# PRU_ICSSG0_PR1_CFG_SLV_local register map
Vendor: Texas Instruments
Peripheral module from a debugger description file (folder am65x).
Registers are 32-bit, read-write, reset 0x0 unless marked. A register's access mark holds for its fields unless they carry their own. Offsets are as the file gives them; lines under a group give offsets from that group; [hi:lo] are bit positions; {n}, {i} and the like mark numbered series; 'fields as' and 'values as' point back to an identical list; <NAME> marks a mode.

## PRU_ICSSG0_PR1_CFG_SLV
0x00 ICSSG_PID_REG ro reset 0x6B00C900 — PID Register.
  [31:0] ICSS_IDVER — Module ID field
0x04 ICSSG_HWDIS_REG ro reset not defined — HW Disable Register
  [7:0] HWDIS — Read the state of the efuse bits which drive pr1_hw_disable[7:0]
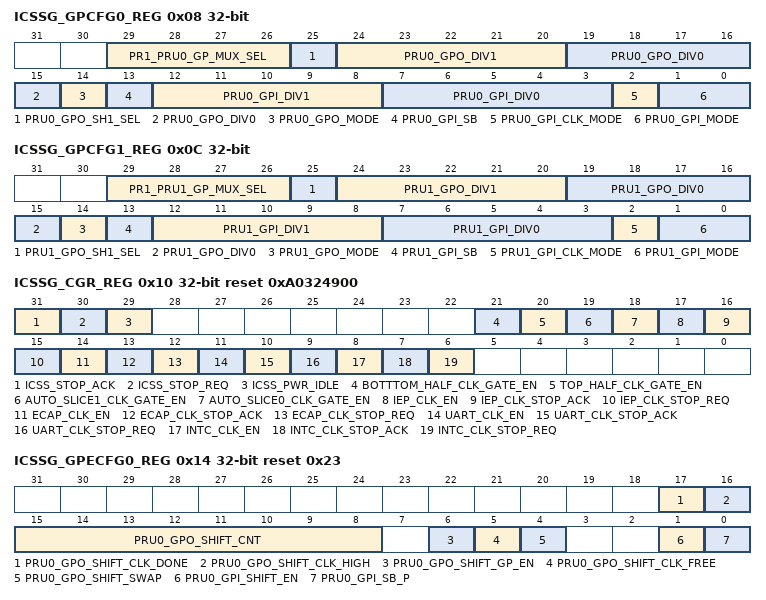
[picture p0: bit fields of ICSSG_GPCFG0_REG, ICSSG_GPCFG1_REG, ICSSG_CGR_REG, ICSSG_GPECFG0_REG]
0x08 ICSSG_GPCFG0_REG access not given — GP Configuration 0 Register
  [29:26] PR1_PRU0_GP_MUX_SEL rw — Controls the icss_wrap mux sel
  [25] PRU0_GPO_SH1_SEL ro — This defines which shadow register is currently getting used for GPO shifting.
  [24:20] PRU0_GPO_DIV1 rw — Divisor value , divide by PRU0_GPO_DIV1 + 1
  [19:15] PRU0_GPO_DIV0 rw — Divisor value , divide by PRU0_GPO_DIV0 + 1
  [14] PRU0_GPO_MODE rw — 0hh = Parallel output mode
  [13] PRU0_GPI_SB — PRU0_GPI_SB set when first capture on 1 on r31_status[0] (access RW1C)
  [12:8] PRU0_GPI_DIV1 rw — Divisor value , divide by PRU0_GPI_DIV1 + 1
  [7:3] PRU0_GPI_DIV0 rw — Divisor value , divide by PRU0_GPI_DIV0 + 1
  [2] PRU0_GPI_CLK_MODE rw — Parallel 16-bit capture mode clock edge
  [1:0] PRU0_GPI_MODE rw — 0hh = Direct connect of pru&lt;n&gt;_r31_status[29:0]
0x0C ICSSG_GPCFG1_REG access not given — GP Configuration 1 Register
  [29:26] PR1_PRU1_GP_MUX_SEL rw — Controls the icss_wrap mux sel
  [25] PRU1_GPO_SH1_SEL ro — This defines which shadow register is currently getting used for GPO shifting.
  [24:20] PRU1_GPO_DIV1 rw — Divisor value , divide by PRU1_GPO_DIV1 + 1
  [19:15] PRU1_GPO_DIV0 rw — Divisor value , divide by PRU1_GPO_DIV0 + 1
  [14] PRU1_GPO_MODE rw — 0hh = Parallel output mode
  [13] PRU1_GPI_SB — PRU1_GPI_SB set when first capture on 1 on r31_status[0] (access RW1C)
  [12:8] PRU1_GPI_DIV1 rw — Divisor value , divide by PRU1_GPI_DIV1 + 1
  [7:3] PRU1_GPI_DIV0 rw — Divisor value , divide by PRU1_GPI_DIV0 + 1
  [2] PRU1_GPI_CLK_MODE rw — Parallel 16-bit capture mode clock edge
  [1:0] PRU1_GPI_MODE rw — 0hh = Direct connect of pru&lt;n&gt;_r31_status[29:0]
0x10 ICSSG_CGR_REG access per field reset 0xA0324900 — Clock Gating Register
  [31] ICSS_STOP_ACK rw — ICSS
  [30] ICSS_STOP_REQ ro — ICSS
  [29] ICSS_PWR_IDLE rw — ICSS
  [21] BOTTTOM_HALF_CLK_GATE_EN rw — Bottom Clock Gate for slice 0 and 1 0 = Disable Clock 1 = Enable Clock
  [20] TOP_HALF_CLK_GATE_EN rw — Top Clock Gate for slice 0 and 1 0 = Disable Clock 1 = Enable Clock
  [19] AUTO_SLICE1_CLK_GATE_EN rw — Auto Clock Gate for slice 1 Ethernet 0 = Disable Clock 1 = Enable Auto Clock
  [18] AUTO_SLICE0_CLK_GATE_EN rw — Auto Clock Gate for slice 0 Ethernet 0 = Disable Clock 1 = Enable Clock
  [17] IEP_CLK_EN rw — IEP
  [16] IEP_CLK_STOP_ACK ro — IEP
  [15] IEP_CLK_STOP_REQ rw — IEP
  [14] ECAP_CLK_EN rw — ECAP
  [13] ECAP_CLK_STOP_ACK ro — ECAP
  [12] ECAP_CLK_STOP_REQ rw — ECAP
  [11] UART_CLK_EN rw — UART
  [10] UART_CLK_STOP_ACK ro — UART
  [9] UART_CLK_STOP_REQ rw — UART
  [8] INTC_CLK_EN rw — INTC
  [7] INTC_CLK_STOP_ACK ro — INTC
  [6] INTC_CLK_STOP_REQ rw — INTC
0x14 ICSSG_GPECFG0_REG reset 0x23 — GP Enc Configuration 0 Register
  [17] PRU0_GPO_SHIFT_CLK_DONE — Shift Clock Done is active when PRU0_GPO_SHIFT_CNT is none zero
  [16] PRU0_GPO_SHIFT_CLK_HIGH — Shift Clock Stop High
  [15:8] PRU0_GPO_SHIFT_CNT — Shift Bit Count
  [6] PRU0_GPO_SHIFT_GP_EN — Enable pru&lt;n&gt;r30[15:2] control during shift out mode
  [5] PRU0_GPO_SHIFT_CLK_FREE — Free Running Clock Mode
  [4] PRU0_GPO_SHIFT_SWAP — 0hh = No Swap
  [1] PRU0_GPI_SHIFT_EN — GPI Shift In Enable
  [0] PRU0_GPI_SB_P — GPI Shift In Start Bit Polarity
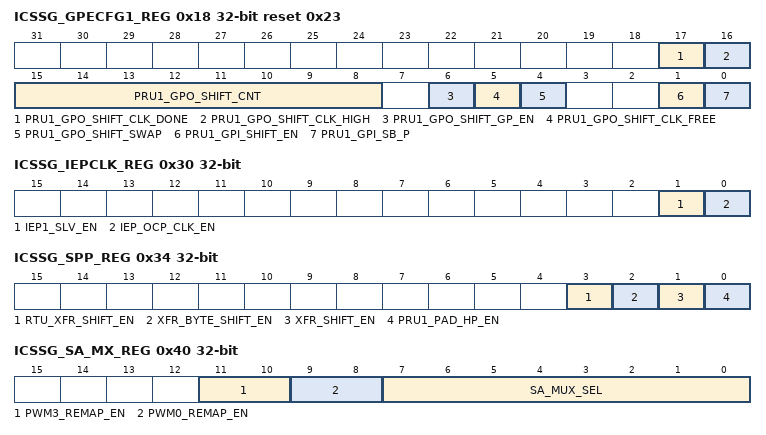
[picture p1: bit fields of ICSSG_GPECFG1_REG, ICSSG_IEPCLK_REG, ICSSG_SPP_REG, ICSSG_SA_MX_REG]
0x18 ICSSG_GPECFG1_REG reset 0x23 — GP Enc Configuration 1 Register
  [17] PRU1_GPO_SHIFT_CLK_DONE — Shift Clock Done is active when PRU1_GPO_SHIFT_CNT is none zero
  [16] PRU1_GPO_SHIFT_CLK_HIGH — Shift Clock Stop High
  [15:8] PRU1_GPO_SHIFT_CNT — Shift Bit Count
  [6] PRU1_GPO_SHIFT_GP_EN — Enable pru&lt;n&gt;r30[15:2] control during shift out mode
  [5] PRU1_GPO_SHIFT_CLK_FREE — Free Running Clock Mode
  [4] PRU1_GPO_SHIFT_SWAP — 0hh = No Swap
  [1] PRU1_GPI_SHIFT_EN — GPI Shift In Enable
  [0] PRU1_GPI_SB_P — GPI Shift In Start Bit Polarity
0x2C ICSSG_MII_RT_REG reset 0x1 — MII_RT Event Enable Register
  [0] MII_RT_EVENT_EN — Enables the MII_RT Events to the INTC
0x30 ICSSG_IEPCLK_REG — IEP Configuration Register
  [1] IEP1_SLV_EN — IEP1 Master Counter Slave enable
  [0] IEP_OCP_CLK_EN — Defines the source of the IEP CLK
0x34 ICSSG_SPP_REG — Scratchpad Priority and Shift Register
  [3] RTU_XFR_SHIFT_EN — Shift enable using R0[4:0] to define the number of 32-bit offset for XIN and XOUT operations.
  [2] XFR_BYTE_SHIFT_EN — Shift enable using R0[6:0] to define the number of 8-bit offset for XIN and XOUT operations.
  [1] XFR_SHIFT_EN — Shift enable using R0[4:0] to define the number of 32-bit offset for XIN and XOUT operations.
  [0] PRU1_PAD_HP_EN — Reserved
0x3C ICSSG_CORE_SYNC_REG — CoreSync Configuration Register.
  [0] CORE_VBUSP_SYNC_EN — Defines the source of the internal CORE CLK
0x40 ICSSG_SA_MX_REG — SA Mux Selection Register.
  [11:10] PWM3_REMAP_EN — PWM3_REMAP_EN controls PRU_ICSSG internal wrapper multiplexing logic.
  [9:8] PWM0_REMAP_EN — PWM0_REMAP_EN controls PRU_ICSSG internal wrapper multiplexing logic.
  [7:0] SA_MUX_SEL — Reserved
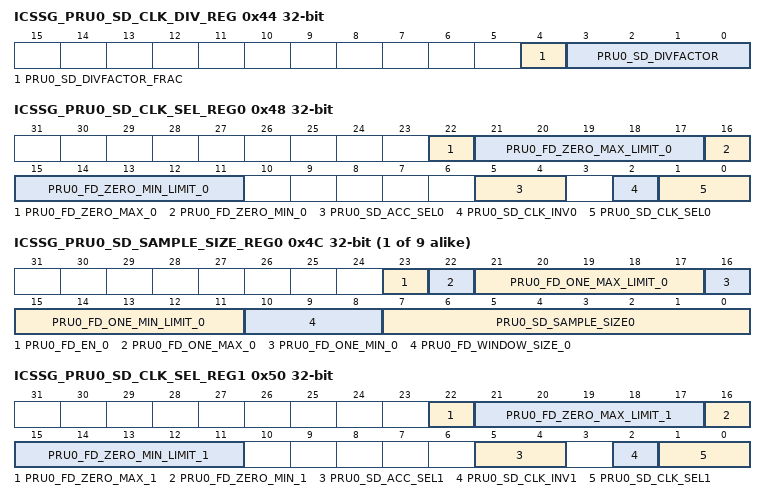
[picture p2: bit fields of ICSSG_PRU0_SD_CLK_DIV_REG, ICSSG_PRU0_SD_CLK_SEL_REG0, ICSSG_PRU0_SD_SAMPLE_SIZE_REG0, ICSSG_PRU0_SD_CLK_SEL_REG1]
0x44 ICSSG_PRU0_SD_CLK_DIV_REG — SD Register.
  [4] PRU0_SD_DIVFACTOR_FRAC, [3:0] PRU0_SD_DIVFACTOR
0x48 ICSSG_PRU0_SD_CLK_SEL_REG0 — PRU0 FD, ACC and Clock Selection Register 0.
  [22] PRU0_FD_ZERO_MAX_0 — Fast Detect Zero Count Max Threshold Hit
  [21:17] PRU0_FD_ZERO_MAX_LIMIT_0 — Fast Detect Zero Count Max Threshold
  [16] PRU0_FD_ZERO_MIN_0 — Fast Detect Zero Count Min Threshold Hit
  [15:11] PRU0_FD_ZERO_MIN_LIMIT_0 — Fast Detect Zero Count Min Threshold
  [5:4] PRU0_SD_ACC_SEL0 — 0h = acc3 is selected
  [2] PRU0_SD_CLK_INV0 — Optional clock inversion post clock selection multiplexer
  [1:0] PRU0_SD_CLK_SEL0 — Selects the clock source
{0x4C+8i} ICSSG_PRU0_SD_SAMPLE_SIZE_REG{i} (i=0..8) — PRU0 FD and Over Sample Size Register {i}.
  [23] PRU0_FD_EN_{i} — Fast Detect One Enable
  [22] PRU0_FD_ONE_MAX_{i} — Fast Detect One Count Max Threshold Hit
  [21:17] PRU0_FD_ONE_MAX_LIMIT_{i} — Fast Detect One Count Max Threshold
  [16] PRU0_FD_ONE_MIN_{i} — Fast Detect One Count Min Threshold Hit
  [15:11] PRU0_FD_ONE_MIN_LIMIT_{i} — Fast Detect One Count Min Threshold
  [10:8] PRU0_FD_WINDOW_SIZE_{i} — Fast Detect Window Size
  [7:0] PRU0_SD_SAMPLE_SIZE{i} — Over Sample Rate
0x50 ICSSG_PRU0_SD_CLK_SEL_REG1 — PRU0 FD, ACC and Clock Selection Register 1.
  [22] PRU0_FD_ZERO_MAX_1 — Fast Detect Zero Count Max Threshold Hit
  [21:17] PRU0_FD_ZERO_MAX_LIMIT_1 — Fast Detect Zero Count Max Threshold
  [16] PRU0_FD_ZERO_MIN_1 — Fast Detect Zero Count Min Threshold Hit
  [15:11] PRU0_FD_ZERO_MIN_LIMIT_1 — Fast Detect Zero Count Min Threshold
  [5:4] PRU0_SD_ACC_SEL1 — 0h = acc3 is selected
  [2] PRU0_SD_CLK_INV1 — Optional clock inversion post clock selection multiplexer
  [1:0] PRU0_SD_CLK_SEL1 — Selects the clock source
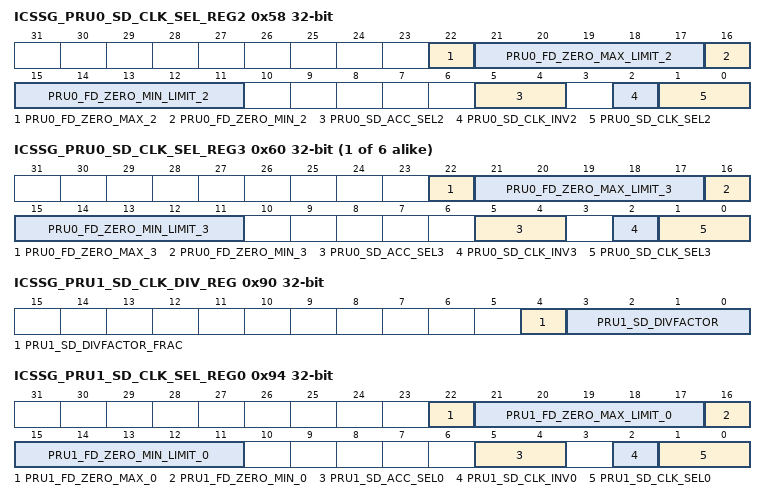
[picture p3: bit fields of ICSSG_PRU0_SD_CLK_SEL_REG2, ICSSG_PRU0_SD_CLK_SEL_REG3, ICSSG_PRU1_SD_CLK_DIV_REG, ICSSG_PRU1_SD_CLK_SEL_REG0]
0x58 ICSSG_PRU0_SD_CLK_SEL_REG2 — PRU0 FD, ACC and Clock Selection Register 2
  [22] PRU0_FD_ZERO_MAX_2 — Fast Detect Zero Count Max Threshold Hit
  [21:17] PRU0_FD_ZERO_MAX_LIMIT_2 — Fast Detect Zero Count Max Threshold
  [16] PRU0_FD_ZERO_MIN_2 — Fast Detect Zero Count Min Threshold Hit
  [15:11] PRU0_FD_ZERO_MIN_LIMIT_2 — Fast Detect Zero Count Min Threshold
  [5:4] PRU0_SD_ACC_SEL2 — 0h = acc3 is selected
  [2] PRU0_SD_CLK_INV2 — Optional clock inversion post clock selection multiplexer
  [1:0] PRU0_SD_CLK_SEL2 — Selects the clock source
{0x48+8i} ICSSG_PRU0_SD_CLK_SEL_REG{i} (i=3..8) — PRU0 FD, ACC and Clock Selection Register {i}.
  [22] PRU0_FD_ZERO_MAX_{i} — Fast Detect Zero Count Max Threshold Hit
  [21:17] PRU0_FD_ZERO_MAX_LIMIT_{i} — Fast Detect Zero Count Max Threshold
  [16] PRU0_FD_ZERO_MIN_{i} — Fast Detect Zero Count Min Threshold Hit
  [15:11] PRU0_FD_ZERO_MIN_LIMIT_{i} — Fast Detect Zero Count Min Threshold
  [5:4] PRU0_SD_ACC_SEL{i} — 0h = acc3 is selected
  [2] PRU0_SD_CLK_INV{i} — Optional clock inversion post clock selection multiplexer
  [1:0] PRU0_SD_CLK_SEL{i} — Selects the clock source
0x90 ICSSG_PRU1_SD_CLK_DIV_REG — SD Register.
  [4] PRU1_SD_DIVFACTOR_FRAC, [3:0] PRU1_SD_DIVFACTOR
0x94 ICSSG_PRU1_SD_CLK_SEL_REG0 — PRU1 FD, ACC and Clock Selection Register 0
  [22] PRU1_FD_ZERO_MAX_0 — Fast Detect Zero Count Max Threshold Hit
  [21:17] PRU1_FD_ZERO_MAX_LIMIT_0 — Fast Detect Zero Count Max Threshold
  [16] PRU1_FD_ZERO_MIN_0 — Fast Detect Zero Count Min Threshold Hit
  [15:11] PRU1_FD_ZERO_MIN_LIMIT_0 — Fast Detect Zero Count Min Threshold
  [5:4] PRU1_SD_ACC_SEL0 — 0h = acc3 is selected
  [2] PRU1_SD_CLK_INV0 — Optional clock inversion post clock selection multiplexer
  [1:0] PRU1_SD_CLK_SEL0 — Selects the clock source
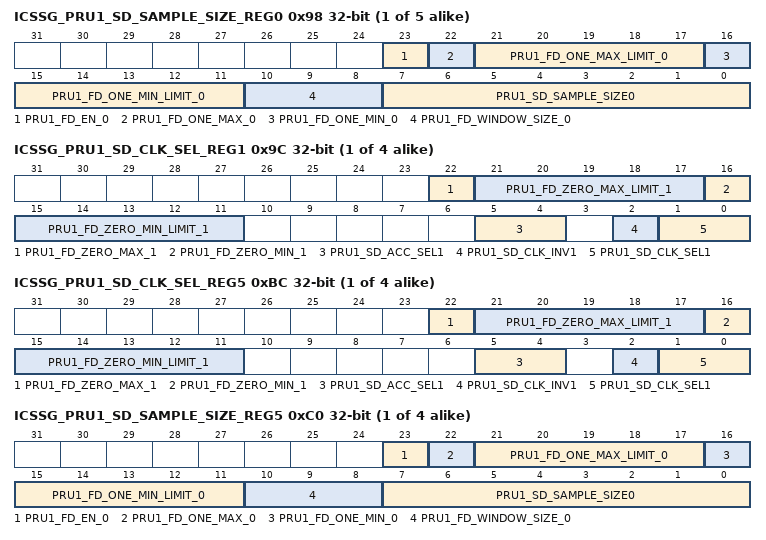
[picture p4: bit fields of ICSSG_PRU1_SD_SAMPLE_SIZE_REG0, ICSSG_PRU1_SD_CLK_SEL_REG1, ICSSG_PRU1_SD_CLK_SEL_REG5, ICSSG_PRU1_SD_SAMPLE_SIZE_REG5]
{0x98+8i} ICSSG_PRU1_SD_SAMPLE_SIZE_REG{i} (i=0..4) — PRU1 FD and Over Sample Size Register {i}.
  [23] PRU1_FD_EN_{i} — Fast Detect One Enable
  [22] PRU1_FD_ONE_MAX_{i} — Fast Detect One Count Max Threshold Hit
  [21:17] PRU1_FD_ONE_MAX_LIMIT_{i} — Fast Detect One Count Max Threshold
  [16] PRU1_FD_ONE_MIN_{i} — Fast Detect One Count Min Threshold Hit
  [15:11] PRU1_FD_ONE_MIN_LIMIT_{i} — Fast Detect One Count Min Threshold
  [10:8] PRU1_FD_WINDOW_SIZE_{i} — Fast Detect Window Size
  [7:0] PRU1_SD_SAMPLE_SIZE{i} — Over Sample Rate
{0x94+8i} ICSSG_PRU1_SD_CLK_SEL_REG{i} (i=1..4) — PRU1 FD, ACC and Clock Selection Register {i}.
  [22] PRU1_FD_ZERO_MAX_{i} — Fast Detect Zero Count Max Threshold Hit
  [21:17] PRU1_FD_ZERO_MAX_LIMIT_{i} — Fast Detect Zero Count Max Threshold
  [16] PRU1_FD_ZERO_MIN_{i} — Fast Detect Zero Count Min Threshold Hit
  [15:11] PRU1_FD_ZERO_MIN_LIMIT_{i} — Fast Detect Zero Count Min Threshold
  [5:4] PRU1_SD_ACC_SEL{i} — 0h = acc3 is selected
  [2] PRU1_SD_CLK_INV{i} — Optional clock inversion post clock selection multiplexer
  [1:0] PRU1_SD_CLK_SEL{i} — Selects the clock source
{0x94+8i} ICSSG_PRU1_SD_CLK_SEL_REG{i} (i=5..8) — PRU1 FD, ACC and Clock Selection Register {i}
  fields as ICSSG_PRU1_SD_CLK_SEL_REG1
{0x98+8i} ICSSG_PRU1_SD_SAMPLE_SIZE_REG{i} (i=5..8) — PRU1 FD and Over Sample Size Register {i}
  fields as ICSSG_PRU1_SD_SAMPLE_SIZE_REG0
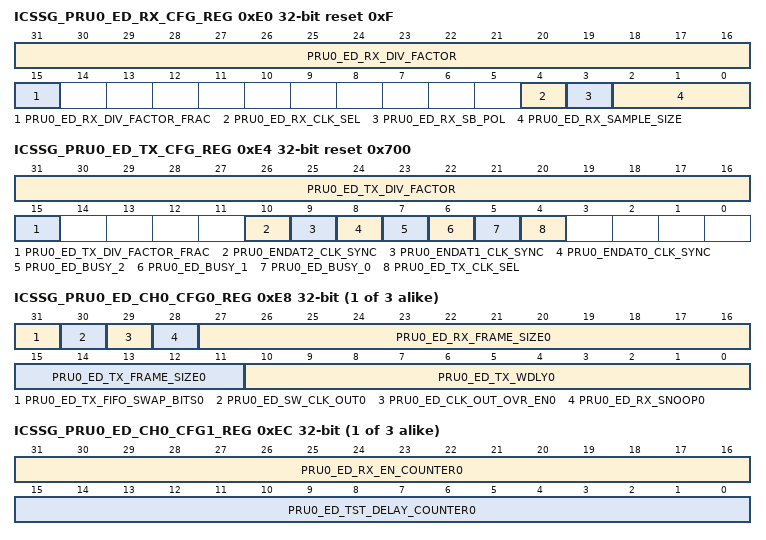
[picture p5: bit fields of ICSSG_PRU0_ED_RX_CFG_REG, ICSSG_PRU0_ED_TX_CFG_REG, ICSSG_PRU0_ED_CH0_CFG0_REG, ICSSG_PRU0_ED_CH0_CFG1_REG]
0xE0 ICSSG_PRU0_ED_RX_CFG_REG reset 0xF — PRU0 ED Receive Global Configuration Register
  [31:16] PRU0_ED_RX_DIV_FACTOR — Div factor for divh16
  [15] PRU0_ED_RX_DIV_FACTOR_FRAC — Enable Fractional division before the divh16
  [4] PRU0_ED_RX_CLK_SEL — Selects the clock source for the divh16fr
  [3] PRU0_ED_RX_SB_POL — Defines the polarity of the RX Start Bit
  [2:0] PRU0_ED_RX_SAMPLE_SIZE — Over Sample size
0xE4 ICSSG_PRU0_ED_TX_CFG_REG access per field reset 0x700 — PRU0 ED Transmit Global Configuration Register
  [31:16] PRU0_ED_TX_DIV_FACTOR rw — Div factor for divh16
  [15] PRU0_ED_TX_DIV_FACTOR_FRAC rw — Enable Fractional division before the divh16
  [10] PRU0_ENDAT2_CLK_SYNC ro — Observation of pru&lt;n&gt;_endat2_clk pin state
  [9] PRU0_ENDAT1_CLK_SYNC ro — Observation of pru&lt;n&gt;_endat1_clk pin state
  [8] PRU0_ENDAT0_CLK_SYNC ro — Observation of pru&lt;n&gt;_endat0_clk pin state
  [7] PRU0_ED_BUSY_2 ro — Determines when you can assert tx go for channel 2
  [6] PRU0_ED_BUSY_1 ro — Determines when you can assert tx go for channel 1
  [5] PRU0_ED_BUSY_0 ro — Determines when you can assert tx go for channel 0
  [4] PRU0_ED_TX_CLK_SEL rw — Selects the clock source for the divh16fr
{0xE8+8i} ICSSG_PRU0_ED_CH{i}_CFG0_REG access per field (i=0..2) — PRU0 ED Channel {i} Configuration 0 Register
  [31] PRU0_ED_TX_FIFO_SWAP_BITS{i} rw — This enables the swapping of the bits when they are loaded into the TX FIFO.
  [30] PRU0_ED_SW_CLK_OUT{i} rw — This controls the state of pru&lt;n&gt;_ endat&lt;m&gt;_clk when endat_clk_out_override_en is set
  [29] PRU0_ED_CLK_OUT_OVR_EN{i} rw — When set, this gives the software the ablity to have direct control of pru&lt;n&gt;_ endat&lt;m&gt;_clk. CAREFUL consideration to not override clock during free running mode of this will cause clock duty cycle violation.
  [28] PRU0_ED_RX_SNOOP{i} ro — Direct Read of pru&lt;n&gt;_ endat&lt;m&gt;_in state
  [27:16] PRU0_ED_RX_FRAME_SIZE{i} rw — RX frame size, after SB is detected
  [15:11] PRU0_ED_TX_FRAME_SIZE{i} rw — TX frame size
  [10:0] PRU0_ED_TX_WDLY{i} rw — EnDAT TX wire delay using 200Mhz steps (CORE clock). Software should program a number divisible by 5. (Hw)
{0xEC+8i} ICSSG_PRU0_ED_CH{i}_CFG1_REG (i=0..2) — PRU0 ED Channel {i} Configuration 1 Register
  [31:16] PRU0_ED_RX_EN_COUNTER{i} — This counter will start counting after the last TX bit is sent and when it expires the HW will automatically arm the receiver (rx_en = 1).
  [15:0] PRU0_ED_TST_DELAY_COUNTER{i} — This counter will start after the tx_wire_delay has been met. After this counter expires the 1st transmit clock will be driven high. Counts in CORE cycles. Software programs value divisible by 5, and hardware will count by 5.
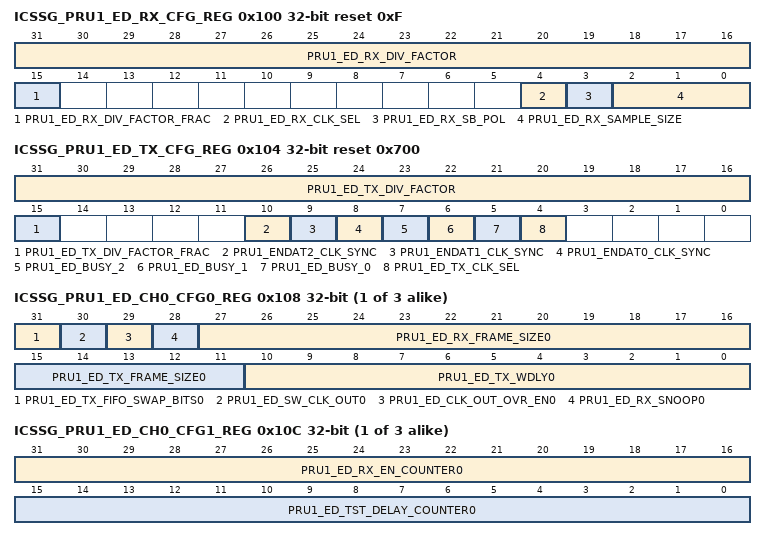
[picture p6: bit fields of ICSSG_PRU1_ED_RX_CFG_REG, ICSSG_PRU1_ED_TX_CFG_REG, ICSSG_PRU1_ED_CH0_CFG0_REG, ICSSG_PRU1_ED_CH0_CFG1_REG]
0x100 ICSSG_PRU1_ED_RX_CFG_REG reset 0xF — PRU1 ED Receive Global Configuration Register.
  [31:16] PRU1_ED_RX_DIV_FACTOR — div factor for divh16
  [15] PRU1_ED_RX_DIV_FACTOR_FRAC — Enable Fractional division before the divh16
  [4] PRU1_ED_RX_CLK_SEL — Selects the clock source for the divh16fr
  [3] PRU1_ED_RX_SB_POL — Defines the polarity of the RX Start Bit
  [2:0] PRU1_ED_RX_SAMPLE_SIZE — Over Sample size
0x104 ICSSG_PRU1_ED_TX_CFG_REG access per field reset 0x700 — PRU1 ED Transmit Global Configuration Register.
  [31:16] PRU1_ED_TX_DIV_FACTOR rw — div factor for divh16
  [15] PRU1_ED_TX_DIV_FACTOR_FRAC rw — Enable Fractional division before the divh16
  [10] PRU1_ENDAT2_CLK_SYNC ro — Observation of pru&lt;n&gt;_endat2_clk pin state
  [9] PRU1_ENDAT1_CLK_SYNC ro — Observation of pru&lt;n&gt;_endat1_clk pin state
  [8] PRU1_ENDAT0_CLK_SYNC ro — Observation of pru&lt;n&gt;_endat0_clk pin state
  [7] PRU1_ED_BUSY_2 ro — Determines when you can assert tx go for channel 2
  [6] PRU1_ED_BUSY_1 ro — Determines when you can assert tx go for channel 1
  [5] PRU1_ED_BUSY_0 ro — Determines when you can assert tx go for channel 0
  [4] PRU1_ED_TX_CLK_SEL rw — Selects the clock source for the divh16fr
{0x108+8i} ICSSG_PRU1_ED_CH{i}_CFG0_REG access per field (i=0..2) — PRU1 ED Channel {i} Configuration 0 Register.
  [31] PRU1_ED_TX_FIFO_SWAP_BITS{i} rw — This enables the swapping of the bits when they are loaded into the TX FIFO.
  [30] PRU1_ED_SW_CLK_OUT{i} rw — This controls the state of pru&lt;n&gt;_ endat&lt;m&gt;_clk when endat_clk_out_override_en is set
  [29] PRU1_ED_CLK_OUT_OVR_EN{i} rw — When set, this gives the software the ablity to have direct control of pru&lt;n&gt;_ endat&lt;m&gt;_clk. CAREFUL consideration to not override clock during free running mode of this will cause clock duty cycle violation.
  [28] PRU1_ED_RX_SNOOP{i} ro — Direct Read of pru&lt;n&gt;_ endat&lt;m&gt;_in state
  [27:16] PRU1_ED_RX_FRAME_SIZE{i} rw — RX frame size, after SB is detected
  [15:11] PRU1_ED_TX_FRAME_SIZE{i} rw — TX frame size
  [10:0] PRU1_ED_TX_WDLY{i} rw — EnDAT TX wire delay using 200Mhz steps (CORE clock). Software should program a number divisible by 5. (Hw)
{0x10C+8i} ICSSG_PRU1_ED_CH{i}_CFG1_REG (i=0..2) — PRU1 ED Channel {i} Configuration 1 Register.
  [31:16] PRU1_ED_RX_EN_COUNTER{i} — This counter will start counting after the last TX bit is sent and when it expires the HW will automatically arm the receiver (rx_en = 1).
  [15:0] PRU1_ED_TST_DELAY_COUNTER{i} — This counter will start after the tx_wire_delay has been met. After this counter expires the 1st transmit clock will be driven high. Counts in CORE cycles. Software programs value divisible by 5, and hardware will count by 5.
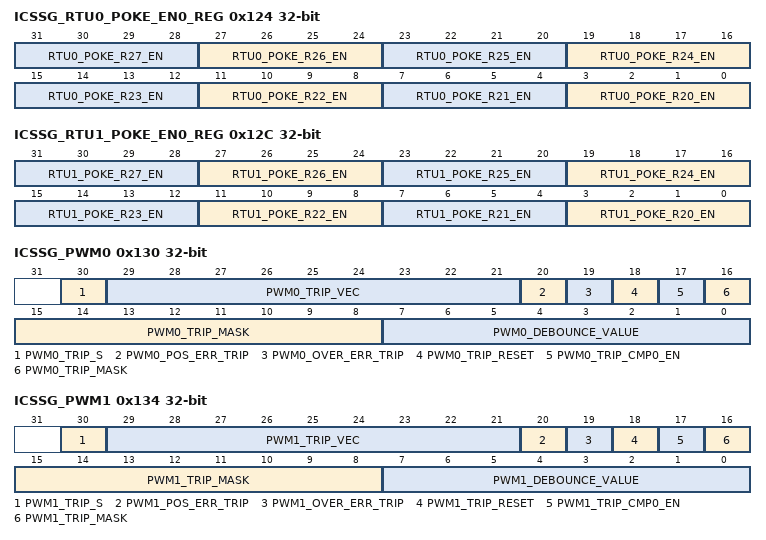
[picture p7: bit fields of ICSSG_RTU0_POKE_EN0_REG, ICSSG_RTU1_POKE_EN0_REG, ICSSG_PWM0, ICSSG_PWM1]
0x124 ICSSG_RTU0_POKE_EN0_REG — RTU0 Poke Enable 0 Register.
  [4n-77:4n-80] RTU0_POKE_R{n}_EN (n=20..27) — This enables the external values to get poked into PRU’s internal register
0x12C ICSSG_RTU1_POKE_EN0_REG — RTU1 Poke Enable 0 Register.
  [4n-77:4n-80] RTU1_POKE_R{n}_EN (n=20..27) — This enables the external values to get poked into PRU’s internal register
0x130 ICSSG_PWM0 access per field — PWM0 Trip Configuration Register.
  [30] PWM0_TRIP_S rw — Trip status.
  [29:21] PWM0_TRIP_VEC ro — Trip trigger cause vector.
  [20] PWM0_POS_ERR_TRIP rw — Software position feedback error trip
  [19] PWM0_OVER_ERR_TRIP rw — Software overcurrent error trip
  [18] PWM0_TRIP_RESET rw — Software trip reset
  [17] PWM0_TRIP_CMP0_EN rw — CMP0 reset trip clear enable
  [16:8] PWM0_TRIP_MASK rw — Software mask for trip, one hot
  [7:0] PWM0_DEBOUNCE_VALUE rw — Debounce counter , defines the number of core_clk required for the pulse not to get rejected
0x134 ICSSG_PWM1 access per field — PWM1 Trip Configuration Register.
  [30] PWM1_TRIP_S rw — Trip status.
  [29:21] PWM1_TRIP_VEC ro — Trip trigger cause vector.
  [20] PWM1_POS_ERR_TRIP rw — Software position feedback error trip
  [19] PWM1_OVER_ERR_TRIP rw — Software overcurrent error trip
  [18] PWM1_TRIP_RESET rw — Software trip reset
  [17] PWM1_TRIP_CMP0_EN rw — CMP0 reset trip clear enable
  [16:8] PWM1_TRIP_MASK rw — Software mask for trip, one hot
  [7:0] PWM1_DEBOUNCE_VALUE rw — Debounce counter, defines the number of core_clk required for the pulse not to get rejected
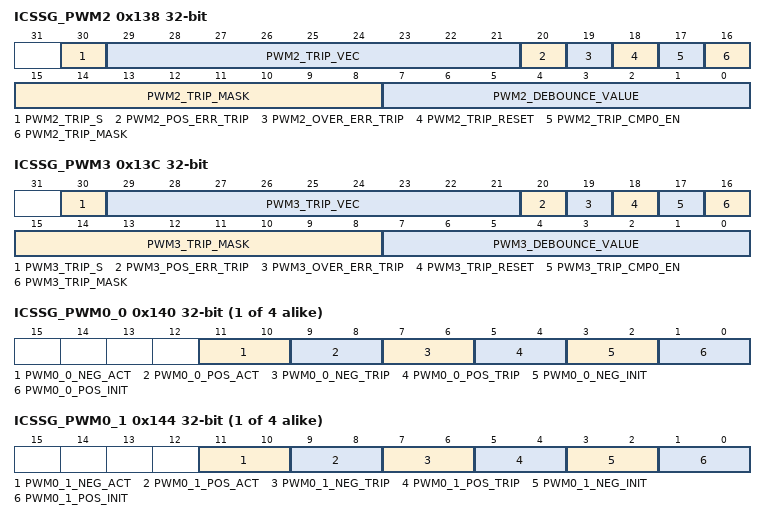
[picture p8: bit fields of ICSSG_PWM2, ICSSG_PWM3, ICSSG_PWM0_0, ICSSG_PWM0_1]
0x138 ICSSG_PWM2 access per field — PWM2 Trip Configuration Register.
  [30] PWM2_TRIP_S rw — Trip status.
  [29:21] PWM2_TRIP_VEC ro — Trip trigger cause vector.
  [20] PWM2_POS_ERR_TRIP rw — Software position feedback error trip
  [19] PWM2_OVER_ERR_TRIP rw — Software overcurrent error trip
  [18] PWM2_TRIP_RESET rw — Software trip reset
  [17] PWM2_TRIP_CMP0_EN rw — CMP0 reset trip clear enable
  [16:8] PWM2_TRIP_MASK rw — Software mask for trip, one hot
  [7:0] PWM2_DEBOUNCE_VALUE rw — Debounce counter, defines the number of core_clk required for the pulse not to get rejected
0x13C ICSSG_PWM3 access per field — PWM3 Trip Configuration Register
  [30] PWM3_TRIP_S rw — Trip status.
  [29:21] PWM3_TRIP_VEC ro — Trip trigger cause vector.
  [20] PWM3_POS_ERR_TRIP rw — Software position feedback error trip
  [19] PWM3_OVER_ERR_TRIP rw — Software overcurrent error trip
  [18] PWM3_TRIP_RESET rw — Software trip reset
  [17] PWM3_TRIP_CMP0_EN rw — CMP0 reset trip clear enable
  [16:8] PWM3_TRIP_MASK rw — Software mask for trip, one hot
  [7:0] PWM3_DEBOUNCE_VALUE rw — Debounce counter, defines the number of core_clk required for the pulse not to get rejected
{0x140+0xC*i} ICSSG_PWM{i}_0 (i=0..3) — PWM{i} State Configuration 0 Register.
  [11:10] PWM{i}_0_NEG_ACT — Active negative state
  [9:8] PWM{i}_0_POS_ACT — Active positive state
  [7:6] PWM{i}_0_NEG_TRIP — Trip negative state
  [5:4] PWM{i}_0_POS_TRIP — Trip positive state
  [3:2] PWM{i}_0_NEG_INIT — Initial negative state
  [1:0] PWM{i}_0_POS_INIT — Initial positive state
{0x144+0xC*i} ICSSG_PWM{i}_1 (i=0..3) — PWM{i} State Configuration 1 Register.
  [11:10] PWM{i}_1_NEG_ACT — Active negative state
  [9:8] PWM{i}_1_POS_ACT — Active positive state
  [7:6] PWM{i}_1_NEG_TRIP — Trip negative state
  [5:4] PWM{i}_1_POS_TRIP — Trip positive state
  [3:2] PWM{i}_1_NEG_INIT — Initial negative state
  [1:0] PWM{i}_1_POS_INIT — Initial positive state
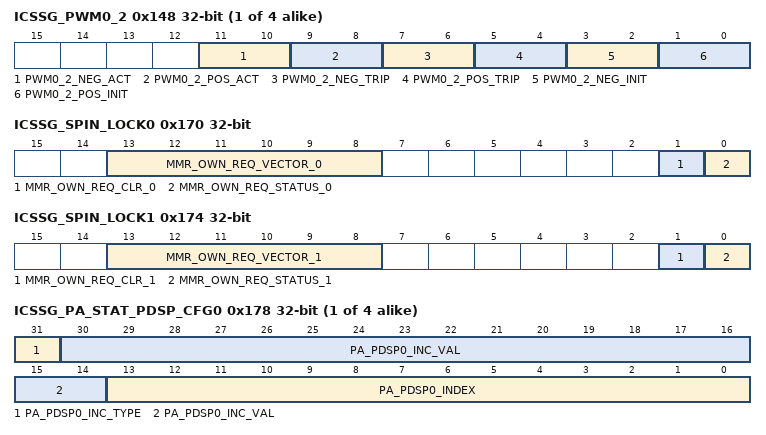
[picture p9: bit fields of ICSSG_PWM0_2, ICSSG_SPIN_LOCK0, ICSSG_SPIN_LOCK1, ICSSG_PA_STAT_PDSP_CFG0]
{0x148+0xC*i} ICSSG_PWM{i}_2 (i=0..3) — PWM{i} State Configuration 2 Register.
  [11:10] PWM{i}_2_NEG_ACT — Active negative state
  [9:8] PWM{i}_2_POS_ACT — Active positive state
  [7:6] PWM{i}_2_NEG_TRIP — Trip negative state
  [5:4] PWM{i}_2_POS_TRIP — Trip positive state
  [3:2] PWM{i}_2_NEG_INIT — Initial negative state
  [1:0] PWM{i}_2_POS_INIT — Initial positive state
0x170 ICSSG_SPIN_LOCK0 access per field (reset mask 0x3F02) — Spin Lock 0 Register.
  [13:8] MMR_OWN_REQ_VECTOR_0 rw — Spin Lock flag Vector
  [1] MMR_OWN_REQ_CLR_0 wo — Spin Lock Status Clear
  [0] MMR_OWN_REQ_STATUS_0 ro — Spin Lock Status
0x174 ICSSG_SPIN_LOCK1 access per field (reset mask 0x3F02) — Spin Lock 1 Register.
  [13:8] MMR_OWN_REQ_VECTOR_1 rw — Spin Lock flag Vector
  [1] MMR_OWN_REQ_CLR_1 wo — Spin Lock Status Clear
  [0] MMR_OWN_REQ_STATUS_1 ro — Spin Lock Status
{0x178+8i} ICSSG_PA_STAT_PDSP_CFG{i} (i=0..3) — PA STATS PRU Vector {i} Register.
  [31] PA_PDSP{i}_INC_TYPE, [30:14] PA_PDSP{i}_INC_VAL, [13:0] PA_PDSP{i}_INDEX
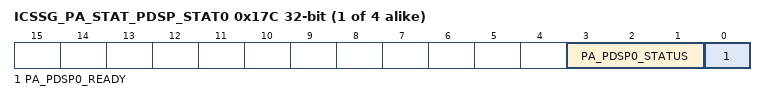
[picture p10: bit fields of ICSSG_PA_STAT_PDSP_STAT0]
{0x17C+8i} ICSSG_PA_STAT_PDSP_STAT{i} ro (i=0..3) — PA STATS PRU Status {i} Register.
  [3:1] PA_PDSP{i}_STATUS, [0] PA_PDSP{i}_READY
